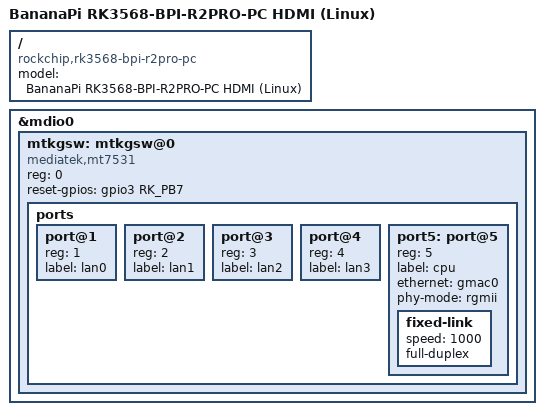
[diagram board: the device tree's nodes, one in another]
// SPDX-License-Identifier: (GPL-2.0+ OR MIT)
/*
 * Copyright (c) 2020 Rockchip Electronics Co., Ltd.
 *
 */

/dts-v1/;

#include "rk3568-bpi-r2pro-pc.dtsi"

/ {
    model = "BananaPi RK3568-BPI-R2PRO-PC HDMI (Linux)";
    compatible = "rockchip,rk3568-bpi-r2pro-pc", "rockchip,rk3568";

    // MT7531 L2 Switch, no DSA feature
/*     mtkgsw: mtkgsw@0 {
	     compatible = "mediatek,mt753x";
	     rockchip,mdio = <&mdio0>;
	     rockchip,portmap = "lllll";
	     rockchip,mdio_master_pinmux = <0>;
	     rockchip,reset-pin = <&gpio3 RK_PB7 GPIO_ACTIVE_HIGH>;
	     status = "okay";

             port5: port@5 {
                     compatible = "mediatek,mt753x-port";
                     reg = <5>;
                     phy-mode = "rgmii";
                     fixed-link {
                             speed = <1000>;
                             full-duplex;
                    };
            };

            port6: port@6 {
                    compatible = "mediatek,mt753x-port";
                    reg = <6>;
                    phy-mode = "sgmii";
                    fixed-link {
                            speed = <2500>;
                            full-duplex;
                   };
           };
     }; */
};   

// MT7531 Switch for DSA feature
&mdio0 {
	mtkgsw: mtkgsw@0 {
		compatible = "mediatek,mt7531";
		reg = <0>;
		reset-gpios = <&gpio3 RK_PB7 GPIO_ACTIVE_HIGH>;

		ports {
			#address-cells = <1>;
			#size-cells = <0>;

			port@1 {
				reg = <1>;
				label = "lan0";
			};

			port@2 {
				reg = <2>;
				label = "lan1";
			};

			port@3 {
				reg = <3>;
				label = "lan2";
			};

			port@4 {
				reg = <4>;
				label = "lan3";
			};

			port5: port@5 {
				reg = <5>;
				label = "cpu";
				ethernet = <&gmac0>;
				phy-mode = "rgmii";
				fixed-link {
					speed = <1000>;
					full-duplex;
				};
			};
		};
	};
};
